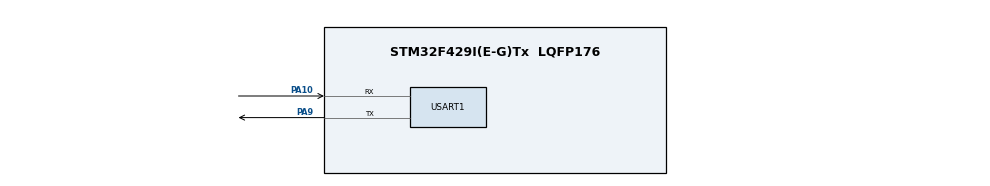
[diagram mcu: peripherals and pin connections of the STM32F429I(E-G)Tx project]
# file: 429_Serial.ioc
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Mcu.Family=STM32F4
Mcu.Name=STM32F429I(E-G)Tx
Mcu.Package=LQFP176
NVIC.PriorityGroup=NVIC_PRIORITYGROUP_4
NVIC.USART1_IRQn=true\:0\:0\:true\:true\:true\:1\:true\:true
PA10.Mode=Asynchronous
PA10.Signal=USART1_RX
PA13.Mode=Serial_Wire
PA13.Signal=SYS_JTMS-SWDIO
PA14.Mode=Serial_Wire
PA14.Signal=SYS_JTCK-SWCLK
PA9.Mode=Asynchronous
PA9.Signal=USART1_TX
PC14/OSC32_IN.Mode=LSE-External-Oscillator
PC14/OSC32_IN.Signal=RCC_OSC32_IN
PC15/OSC32_OUT.Mode=LSE-External-Oscillator
PC15/OSC32_OUT.Signal=RCC_OSC32_OUT
PH0/OSC_IN.Mode=HSE-External-Oscillator
PH0/OSC_IN.Signal=RCC_OSC_IN
PH1/OSC_OUT.Mode=HSE-External-Oscillator
PH1/OSC_OUT.Signal=RCC_OSC_OUT
ProjectManager.HeapSize=0x200
ProjectManager.StackSize=0x400
ProjectManager.TargetToolchain=MDK-ARM V5
RCC.48MHZClocksFreq_Value=40000000
RCC.AHBFreq_Value=80000000
RCC.APB1CLKDivider=RCC_HCLK_DIV2
RCC.APB1Freq_Value=40000000
RCC.APB1TimFreq_Value=80000000
RCC.APB2CLKDivider=RCC_HCLK_DIV2
RCC.APB2Freq_Value=40000000
RCC.APB2TimFreq_Value=80000000
RCC.CortexFreq_Value=80000000
RCC.HCLKFreq_Value=80000000
RCC.HSE_VALUE=25000000
RCC.HSI_VALUE=16000000
RCC.PLLM=15
RCC.PLLN=96
RCC.PLLSourceVirtual=RCC_PLLSOURCE_HSE
RCC.SYSCLKFreq_VALUE=80000000
RCC.SYSCLKSource=RCC_SYSCLKSOURCE_PLLCLK
RCC.VCOOutputFreq_Value=160000000
USART1.VirtualMode=VM_ASYNC
board=custom

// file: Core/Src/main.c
/* USER CODE BEGIN Header */
/**
  ******************************************************************************
  * @file           : main.c
  * @brief          : Main program body
  ******************************************************************************
  * @attention
  *
  * <h2><center>&copy; Copyright (c) 2022 STMicroelectronics.
  * All rights reserved.</center></h2>
  *
  * This software component is licensed by ST under BSD 3-Clause license,
  * the "License"; You may not use this file except in compliance with the
  * License. You may obtain a copy of the License at:
  *                        opensource.org/licenses/BSD-3-Clause
  *
  ******************************************************************************
  */
/* USER CODE END Header */
#include "main.h"
#include "usart.h"
#include "gpio.h"

/* USER CODE BEGIN Includes */
#include "stdio.h"
/* USER CODE END Includes */

/* USER CODE BEGIN PV */
uint8_t tx_buff[16];
uint8_t rx_buff[16];
/* USER CODE END PV */

void SystemClock_Config(void);
static void MX_NVIC_Init(void);

int main(void)
{

  /* MCU Configuration--------------------------------------------------------*/

  /* Reset of all peripherals, Initializes the Flash interface and the Systick. */

  LL_APB2_GRP1_EnableClock(LL_APB2_GRP1_PERIPH_SYSCFG);
  LL_APB1_GRP1_EnableClock(LL_APB1_GRP1_PERIPH_PWR);

  NVIC_SetPriorityGrouping(NVIC_PRIORITYGROUP_4);

  /* System interrupt init*/
  /* SysTick_IRQn interrupt configuration */
  NVIC_SetPriority(SysTick_IRQn, NVIC_EncodePriority(NVIC_GetPriorityGrouping(),15, 0));

  /* Configure the system clock */
  SystemClock_Config();

  /* Initialize all configured peripherals */
  MX_GPIO_Init();
  MX_USART1_UART_Init();

  /* Initialize interrupts */
  MX_NVIC_Init();
  /* USER CODE BEGIN 2 */
	LL_USART_EnableIT_RXNE(USART1);
	LL_USART_EnableIT_IDLE(USART1);
	for(int i = 0; i<=1; i++)
	{
		printf("Can you hear me~ <===\r\n");
	}
  /* USER CODE END 2 */

  /* Infinite loop */
  while (1)
  {

	}
}

void SystemClock_Config(void)
{
  LL_FLASH_SetLatency(LL_FLASH_LATENCY_2);
  while(LL_FLASH_GetLatency()!= LL_FLASH_LATENCY_2)
  {
  }
  LL_PWR_SetRegulVoltageScaling(LL_PWR_REGU_VOLTAGE_SCALE3);
  LL_PWR_DisableOverDriveMode();
  LL_RCC_HSE_Enable();

   /* Wait till HSE is ready */
  while(LL_RCC_HSE_IsReady() != 1)
  {

  }
  LL_RCC_PLL_ConfigDomain_SYS(LL_RCC_PLLSOURCE_HSE, LL_RCC_PLLM_DIV_15, 96, LL_RCC_PLLP_DIV_2);
  LL_RCC_PLL_Enable();

   /* Wait till PLL is ready */
  while(LL_RCC_PLL_IsReady() != 1)
  {

  }
  LL_RCC_SetAHBPrescaler(LL_RCC_SYSCLK_DIV_1);
  LL_RCC_SetAPB1Prescaler(LL_RCC_APB1_DIV_2);
  LL_RCC_SetAPB2Prescaler(LL_RCC_APB2_DIV_2);
  LL_RCC_SetSysClkSource(LL_RCC_SYS_CLKSOURCE_PLL);

   /* Wait till System clock is ready */
  while(LL_RCC_GetSysClkSource() != LL_RCC_SYS_CLKSOURCE_STATUS_PLL)
  {

  }
  LL_Init1msTick(80000000);
  LL_SetSystemCoreClock(80000000);
  LL_RCC_SetTIMPrescaler(LL_RCC_TIM_PRESCALER_TWICE);
}

/**
  * @brief NVIC Configuration.
  * @retval None
  */
static void MX_NVIC_Init(void)
{
  /* USART1_IRQn interrupt configuration */
  NVIC_SetPriority(USART1_IRQn, NVIC_EncodePriority(NVIC_GetPriorityGrouping(),0, 0));
  NVIC_EnableIRQ(USART1_IRQn);
}

void Error_Handler(void)
{
  __disable_irq();
  while (1)
  {
  }
}

/************************ (C) COPYRIGHT STMicroelectronics *****END OF FILE****/
